# MEMISO register map
Registers from a debugger description file.
Registers are 32-bit, access not given, no defined reset value unless marked. A register's access mark holds for its fields unless they carry their own. Addresses are absolute; registers are grouped by the start of their names; lines under a group give offsets from that group; [hi:lo] are bit positions; {n}, {i} and the like mark numbered series; 'fields as' and 'values as' point back to an identical list; <NAME> marks a mode.

## AddressFilterEnable
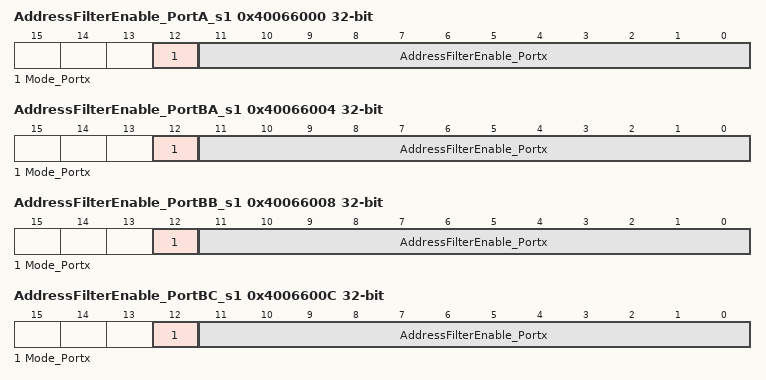
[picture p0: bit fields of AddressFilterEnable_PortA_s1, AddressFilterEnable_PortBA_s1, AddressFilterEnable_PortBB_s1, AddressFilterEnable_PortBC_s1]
0x40066000 AddressFilterEnable_PortA_s1
  [12] Mode_Portx, [11:0] AddressFilterEnable_Portx
0x40066004 AddressFilterEnable_PortBA_s1
  [12] Mode_Portx, [11:0] AddressFilterEnable_Portx
0x40066008 AddressFilterEnable_PortBB_s1
  [12] Mode_Portx, [11:0] AddressFilterEnable_Portx
0x4006600C AddressFilterEnable_PortBC_s1
  [12] Mode_Portx, [11:0] AddressFilterEnable_Portx
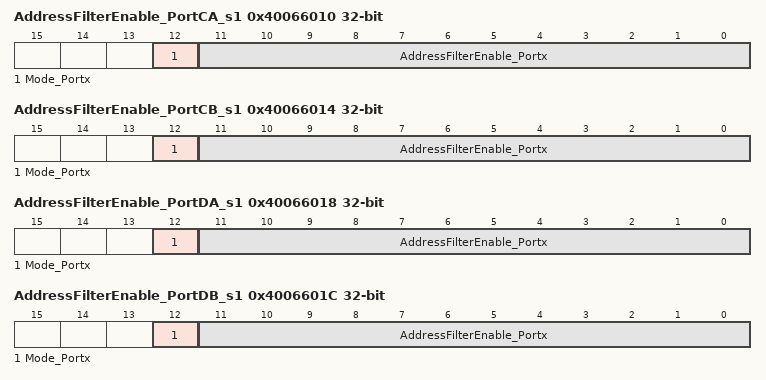
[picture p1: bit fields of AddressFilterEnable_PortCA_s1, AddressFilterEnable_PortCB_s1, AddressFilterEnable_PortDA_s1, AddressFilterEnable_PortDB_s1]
0x40066010 AddressFilterEnable_PortCA_s1
  [12] Mode_Portx, [11:0] AddressFilterEnable_Portx
0x40066014 AddressFilterEnable_PortCB_s1
  [12] Mode_Portx, [11:0] AddressFilterEnable_Portx
0x40066018 AddressFilterEnable_PortDA_s1
  [12] Mode_Portx, [11:0] AddressFilterEnable_Portx
0x4006601C AddressFilterEnable_PortDB_s1
  [12] Mode_Portx, [11:0] AddressFilterEnable_Portx
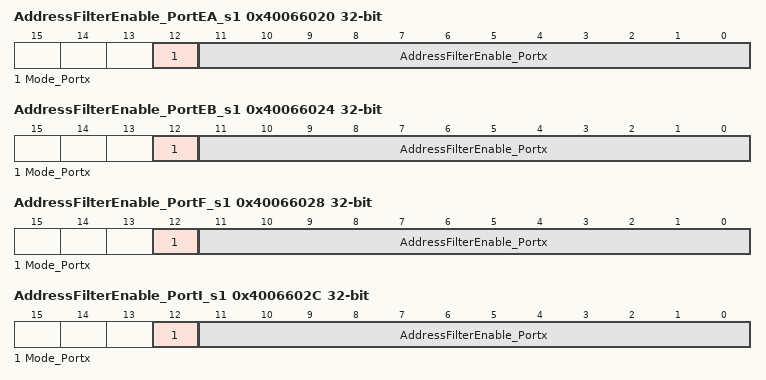
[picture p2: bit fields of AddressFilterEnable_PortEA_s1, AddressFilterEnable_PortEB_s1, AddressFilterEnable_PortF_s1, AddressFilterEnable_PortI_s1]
0x40066020 AddressFilterEnable_PortEA_s1
  [12] Mode_Portx, [11:0] AddressFilterEnable_Portx
0x40066024 AddressFilterEnable_PortEB_s1
  [12] Mode_Portx, [11:0] AddressFilterEnable_Portx
0x40066028 AddressFilterEnable_PortF_s1
  [12] Mode_Portx, [11:0] AddressFilterEnable_Portx
0x4006602C AddressFilterEnable_PortI_s1
  [12] Mode_Portx, [11:0] AddressFilterEnable_Portx
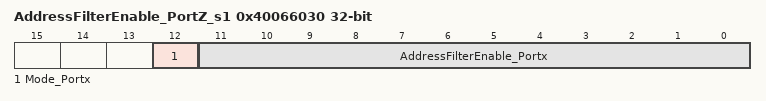
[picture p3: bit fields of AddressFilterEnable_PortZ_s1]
0x40066030 AddressFilterEnable_PortZ_s1
  [12] Mode_Portx, [11:0] AddressFilterEnable_Portx

## AddressFilter
0x40066100 AddressFilter_PortA_s1
  [11:0] AddressFilter_Portx
0x40066104 AddressFilter_PortBA_s1
  [11:0] AddressFilter_Portx
0x40066108 AddressFilter_PortBB_s1
  [11:0] AddressFilter_Portx
0x4006610C AddressFilter_PortBC_s1
  [11:0] AddressFilter_Portx
0x40066110 AddressFilter_PortCA_s1
  [11:0] AddressFilter_Portx
0x40066114 AddressFilter_PortCB_s1
  [11:0] AddressFilter_Portx
0x40066118 AddressFilter_PortDA_s1
  [11:0] AddressFilter_Portx
0x4006611C AddressFilter_PortDB_s1
  [11:0] AddressFilter_Portx
0x40066120 AddressFilter_PortEA_s1
  [11:0] AddressFilter_Portx
0x40066124 AddressFilter_PortEB_s1
  [11:0] AddressFilter_Portx
0x40066128 AddressFilter_PortF_s1
  [11:0] AddressFilter_Portx
0x4006612C AddressFilter_PortI_s1
  [11:0] AddressFilter_Portx
0x40066130 AddressFilter_PortZ_s1
  [11:0] AddressFilter_Portx

## VerifiedAddress
0x40066200 VerifiedAddress_PortA_s1
  [11:0] VerifiedAddress_Portx
0x40066204 VerifiedAddress_PortBA_s1
  [11:0] VerifiedAddress_Portx
0x40066208 VerifiedAddress_PortBB_s1
  [11:0] VerifiedAddress_Portx
0x4006620C VerifiedAddress_PortBC_s1
  [11:0] VerifiedAddress_Portx
0x40066210 VerifiedAddress_PortCA_s1
  [11:0] VerifiedAddress_Portx
0x40066214 VerifiedAddress_PortCB_s1
  [11:0] VerifiedAddress_Portx
0x40066218 VerifiedAddress_PortDA_s1
  [11:0] VerifiedAddress_Portx
0x4006621C VerifiedAddress_PortDB_s1
  [11:0] VerifiedAddress_Portx
0x40066220 VerifiedAddress_PortEA_s1
  [11:0] VerifiedAddress_Portx
0x40066224 VerifiedAddress_PortEB_s1
  [11:0] VerifiedAddress_Portx
0x40066228 VerifiedAddress_PortF_s1
  [11:0] VerifiedAddress_Portx
0x4006622C VerifiedAddress_PortI_s1
  [11:0] VerifiedAddress_Portx
0x40066230 VerifiedAddress_PortZ_s1
  [11:0] VerifiedAddress_Portx

## StatusAddress
0x40066300 StatusAddress_PortA_s1
  [1:0] StatusAddress_Portx
0x40066304 StatusAddress_PortBA_s1
  [1:0] StatusAddress_Portx
0x40066308 StatusAddress_PortBB_s1
  [1:0] StatusAddress_Portx
0x4006630C StatusAddress_PortBC_s1
  [1:0] StatusAddress_Portx
0x40066310 StatusAddress_PortCA_s1
  [1:0] StatusAddress_Portx
0x40066314 StatusAddress_PortCB_s1
  [1:0] StatusAddress_Portx
0x40066318 StatusAddress_PortDA_s1
  [1:0] StatusAddress_Portx
0x4006631C StatusAddress_PortDB_s1
  [1:0] StatusAddress_Portx
0x40066320 StatusAddress_PortEA_s1
  [1:0] StatusAddress_Portx
0x40066324 StatusAddress_PortEB_s1
  [1:0] StatusAddress_Portx
0x40066328 StatusAddress_PortF_s1
  [1:0] StatusAddress_Portx
0x4006632C StatusAddress_PortI_s1
  [1:0] StatusAddress_Portx
0x40066330 StatusAddress_PortZ_s1
  [1:0] StatusAddress_Portx

## SFR
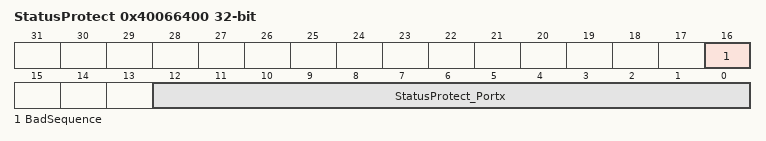
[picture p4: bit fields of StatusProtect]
0x40066400 StatusProtect
  [16] BadSequence, [12:0] StatusProtect_Portx
